# SERDES0 register map
Vendor: Texas Instruments
Registers are 32-bit, read-write, reset 0x0 unless marked. A register's access mark holds for its fields unless they carry their own. Offsets are as the file gives them; [hi:lo] are bit positions; {n}, {i} and the like mark numbered series.

## SERDES0 (part 2 of 2)
0x00 CMU_R000 reset 0x17000000 — The cmu_000 register
  [30:24] CMU_PLL_CTRL1_6_0_O — CMU PLL control 1 register [6:0]
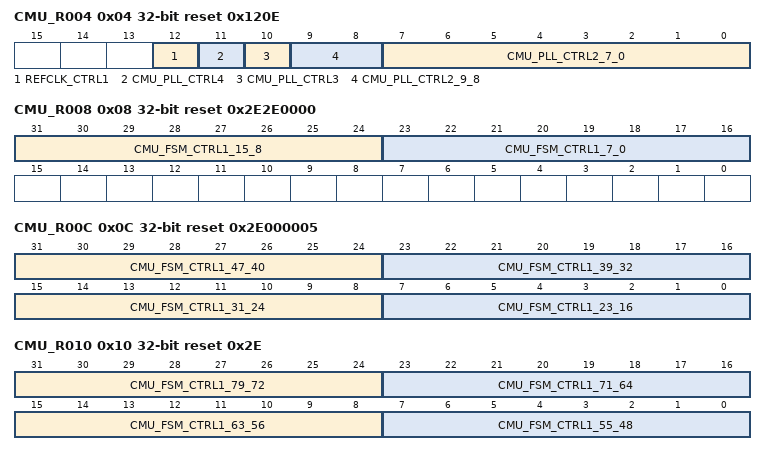
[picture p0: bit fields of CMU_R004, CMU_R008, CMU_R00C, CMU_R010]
0x04 CMU_R004 reset 0x120E — The cmu_004 register
  [12] REFCLK_CTRL1 — Refclk control 1 register
  [11] CMU_PLL_CTRL4 — CMU PLL control 4 register
  [10] CMU_PLL_CTRL3 — CMU PLL control 3 register
  [9:8] CMU_PLL_CTRL2_9_8 — CMU PLL control 2 register [9:8]
  [7:0] CMU_PLL_CTRL2_7_0 — CMU PLL control 2 register [7:0]
0x08 CMU_R008 reset 0x2E2E0000 — The cmu_008 register
  [31:24] CMU_FSM_CTRL1_15_8 — CMU FSM control 1 register 15-8
  [23:16] CMU_FSM_CTRL1_7_0 — CMU FSM control 1 register 7-0
0x0C CMU_R00C reset 0x2E000005 — The cmu_00c register
  [31:24] CMU_FSM_CTRL1_47_40 — CMU FSM control 1 register 47-40
  [23:16] CMU_FSM_CTRL1_39_32 — CMU FSM control 1 register 39-32
  [15:8] CMU_FSM_CTRL1_31_24 — CMU FSM control 1 register 31-24
  [7:0] CMU_FSM_CTRL1_23_16 — CMU FSM control 1 register 23-16
0x10 CMU_R010 reset 0x2E — The cmu_010 register
  [31:24] CMU_FSM_CTRL1_79_72 — CMU FSM control 1 register 79-72
  [23:16] CMU_FSM_CTRL1_71_64 — CMU FSM control 1 register 71-64
  [15:8] CMU_FSM_CTRL1_63_56 — CMU FSM control 1 register 63-56
  [7:0] CMU_FSM_CTRL1_55_48 — CMU FSM control 1 register 55-48
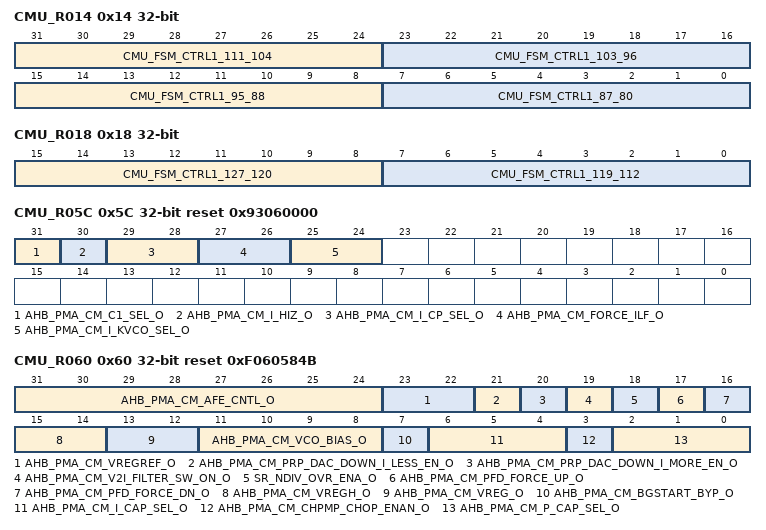
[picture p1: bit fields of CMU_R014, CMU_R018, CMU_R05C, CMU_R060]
0x14 CMU_R014 — The cmu_014 register
  [31:24] CMU_FSM_CTRL1_111_104 — CMU FSM control 1 register 111-104
  [23:16] CMU_FSM_CTRL1_103_96 — CMU FSM control 1 register 103-96
  [15:8] CMU_FSM_CTRL1_95_88 — CMU FSM control 1 register 95-88
  [7:0] CMU_FSM_CTRL1_87_80 — CMU FSM control 1 register 87-80
0x18 CMU_R018 — The cmu_018 register
  [15:8] CMU_FSM_CTRL1_127_120 — CMU FSM control 1 register 127-120
  [7:0] CMU_FSM_CTRL1_119_112 — CMU FSM control 1 register 119-112
0x5C CMU_R05C reset 0x93060000 — The cmu_05c register
  [31] AHB_PMA_CM_C1_SEL_O — CMU LF C1 cap select. Enabling increases C1 cap.
  [30] AHB_PMA_CM_I_HIZ_O — CMU PLL HIZ setting
  [29:28] AHB_PMA_CM_I_CP_SEL_O — Charge pump current gain select.
  [27:26] AHB_PMA_CM_FORCE_ILF_O — CMU loop filter force to common mode
  [25:24] AHB_PMA_CM_I_KVCO_SEL_O — CMU VCO integral path gain
0x60 CMU_R060 reset 0xF060584B — The cmu_060 register
  [31:24] AHB_PMA_CM_AFE_CNTL_O — CMU AFE spares
  [23:22] AHB_PMA_CM_VREGREF_O — CMU reference clock regulator setting
  [21] AHB_PMA_CM_PRP_DAC_DOWN_I_LESS_EN_O — CMU VCO PMOS proportional current decrease
  [20] AHB_PMA_CM_PRP_DAC_DOWN_I_MORE_EN_O — CMU VCO PMOS proportional current increase
  [19] AHB_PMA_CM_V2I_FILTER_SW_ON_O — CMU V2I filter enable
  [18] SR_NDIV_OVR_ENA_O — Override enable for overriding N-div value
  [17] AHB_PMA_CM_PFD_FORCE_UP_O — Force PFD to output up
  [16] AHB_PMA_CM_PFD_FORCE_DN_O — Force PFD to output down
  [15:14] AHB_PMA_CM_VREGH_O — CMU VREGH setting
  [13:12] AHB_PMA_CM_VREG_O — CMU VREG setting
  [11:8] AHB_PMA_CM_VCO_BIAS_O — CMU VCO bias current setting.
  [7] AHB_PMA_CM_BGSTART_BYP_O — Bandgap startup circuit bypass
  [6:4] AHB_PMA_CM_I_CAP_SEL_O — CMU VCO integral path cap select
  [3] AHB_PMA_CM_CHPMP_CHOP_ENAN_O — Charge pump chop enable
  [2:0] AHB_PMA_CM_P_CAP_SEL_O — CMU VCO proportional path cap select
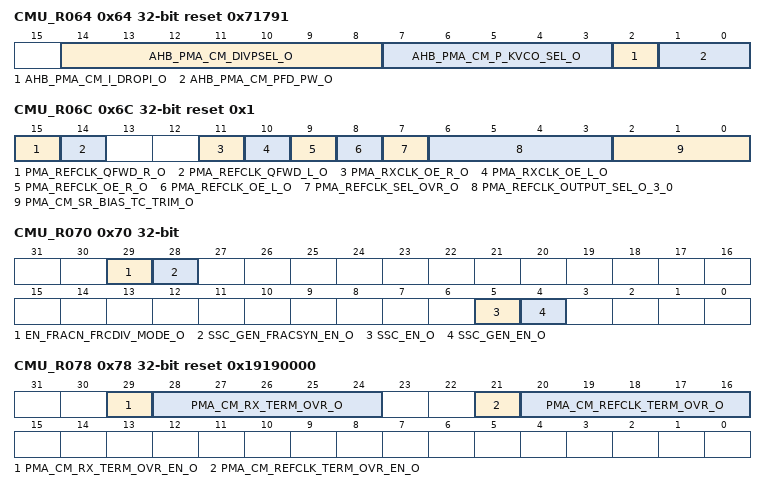
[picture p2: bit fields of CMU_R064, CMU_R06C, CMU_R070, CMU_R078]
0x64 CMU_R064 reset 0x71791 — The cmu_064 register
  [14:8] AHB_PMA_CM_DIVPSEL_O — CMU P-divider setting
  [7:3] AHB_PMA_CM_P_KVCO_SEL_O — CMU PLL KVCO setting
  [2] AHB_PMA_CM_I_DROPI_O — Enable to reduce charge pump reference current
  [1:0] AHB_PMA_CM_PFD_PW_O — PFD pulse width setting
0x6C CMU_R06C reset 0x1 — The cmu_06c register
  [15] PMA_REFCLK_QFWD_R_O — Override for primary IO: refclk_qfwd_r_i Enabled by pma_refclk_sel_ovr_o
  [14] PMA_REFCLK_QFWD_L_O — Override for primary IO: refclk_qfwd_l_i Enabled by pma_refclk_sel_ovr_o
  [11] PMA_RXCLK_OE_R_O — Override for primary IO: rxclk_oe_l_i Enabled by pma_refclk_sel_ovr_o
  [10] PMA_RXCLK_OE_L_O — 'Override for primary IO: rxclk_oe_l_i Enabled by pma_refclk_sel_ovr_o'
  [9] PMA_REFCLK_OE_R_O — 'Override for primary IO: refclk_oe_r_i Enabled by pma_refclk_sel_ovr_o'
  [8] PMA_REFCLK_OE_L_O — Override for primary IO: refclk_oe_l_i Enabled by pma_refclk_sel_ovr_o
  [7] PMA_REFCLK_SEL_OVR_O — Reference clock select override
  [6:3] PMA_REFCLK_OUTPUT_SEL_O_3_0 — Reference clock output select
  [2:0] PMA_CM_SR_BIAS_TC_TRIM_O — sr bias tc trim drving to PMA
0x70 CMU_R070 — The cmu_070 register
  [29] EN_FRACN_FRCDIV_MODE_O — Enable fractional division mode and SSC mode
  [28] SSC_GEN_FRACSYN_EN_O — Enable for SSC generator with Fractional Synthesis
  [5] SSC_EN_O — Active high Enable for SSC block synth or SSC mode
  [4] SSC_GEN_EN_O — Active high Enable for SSC generator SSC mode
0x74 CMU_R074 — The cmu_074 register
0x78 CMU_R078 reset 0x19190000 — The cmu_078 register
  [29] PMA_CM_RX_TERM_OVR_EN_O — Rx Termination override enable
  [28:24] PMA_CM_RX_TERM_OVR_O — Rx Termination override value, every rx lane gets the same value
  [21] PMA_CM_REFCLK_TERM_OVR_EN_O — Refclk Termination override enable
  [20:16] PMA_CM_REFCLK_TERM_OVR_O — Refclk Termination override value
0x7C CMU_R07C reset 0x100920A — The cmu_07c register
  [24] CMU_MASTER_CDN_O — Master reset for CMU
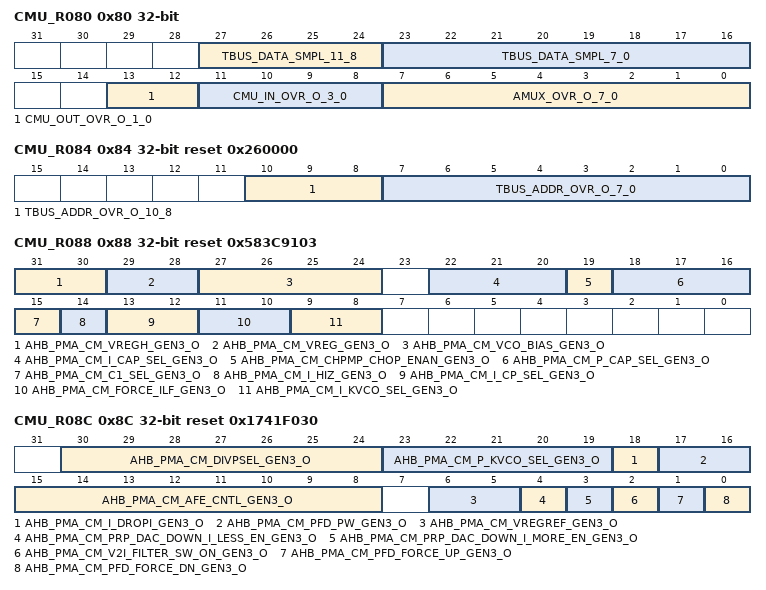
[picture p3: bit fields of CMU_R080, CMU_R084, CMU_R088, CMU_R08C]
0x80 CMU_R080 access per field — The cmu_080 register
  [27:24] TBUS_DATA_SMPL_11_8 ro — Snapshot of digital test bus data [11:8]
  [23:16] TBUS_DATA_SMPL_7_0 ro — Snapshot of digital test bus data [7:0]
  [13:12] CMU_OUT_OVR_O_1_0 rw — Override for Reset_smu_fl
  [11:8] CMU_IN_OVR_O_3_0 rw — Override for following CMU Control Signals [2] - active high, override enable [1] - CMU Powerdown Pin IO [0] - CMU Reset Pin IO
  [7:0] AMUX_OVR_O_7_0 rw — Not used
0x84 CMU_R084 reset 0x260000 — The cmu_084 register
  [10:8] TBUS_ADDR_OVR_O_10_8 — CMU Test Bus address 10-8
  [7:0] TBUS_ADDR_OVR_O_7_0 — CMU Test Bus address 7-0
0x88 CMU_R088 reset 0x583C9103 — The cmu_088 register
  [31:30] AHB_PMA_CM_VREGH_GEN3_O — CMU VREGH setting in gen3 rate Used only in PCIe3 1CMU config
  [29:28] AHB_PMA_CM_VREG_GEN3_O — CMU VREG setting in gen3 rate Used only in PCIe3 1CMU config
  [27:24] AHB_PMA_CM_VCO_BIAS_GEN3_O — CMU VCO bias current setting
  [22:20] AHB_PMA_CM_I_CAP_SEL_GEN3_O — CMU VCO integral path cap select
  [19] AHB_PMA_CM_CHPMP_CHOP_ENAN_GEN3_O — Charge pump chop enable in gen3 rate Used only in PCIe3 1CMU config
  [18:16] AHB_PMA_CM_P_CAP_SEL_GEN3_O — CMU VCO proportional path cap select
  [15] AHB_PMA_CM_C1_SEL_GEN3_O — CMU LF C1 cap select. Enabling increases C1 cap.
  [14] AHB_PMA_CM_I_HIZ_GEN3_O — CMU PLL HIZ setting in gen3 rate Used only in PCIe3 1CMU config
  [13:12] AHB_PMA_CM_I_CP_SEL_GEN3_O — Charge pump current gain select.
  [11:10] AHB_PMA_CM_FORCE_ILF_GEN3_O — CMU LF Force value in gen3 rate Used only in PCIe3 1CMU config
  [9:8] AHB_PMA_CM_I_KVCO_SEL_GEN3_O — CMU VCO proportional current gain
0x8C CMU_R08C reset 0x1741F030 — The cmu_08c register
  [30:24] AHB_PMA_CM_DIVPSEL_GEN3_O — CMU P-divider setting in gen3 rate Used only in PCIe3 1CMU config
  [23:19] AHB_PMA_CM_P_KVCO_SEL_GEN3_O — CMU PLL KVCO setting in gen3 rate Used only in PCIe3 1CMU config
  [18] AHB_PMA_CM_I_DROPI_GEN3_O — Enable to reduce charge pump reference current
  [17:16] AHB_PMA_CM_PFD_PW_GEN3_O — PFD pulse width setting in gen3 rate Used only in PCIe3 1CMU config
  [15:8] AHB_PMA_CM_AFE_CNTL_GEN3_O — CMU AFE spares in gen3 rate Used only in PCIe3 1CMU config
  [6:5] AHB_PMA_CM_VREGREF_GEN3_O — CMU VDREGREF setting
  [4] AHB_PMA_CM_PRP_DAC_DOWN_I_LESS_EN_GEN3_O — CMU VCO PMOS proportional current decrease
  [3] AHB_PMA_CM_PRP_DAC_DOWN_I_MORE_EN_GEN3_O — CMU VCO PMOS proportional current increase
  [2] AHB_PMA_CM_V2I_FILTER_SW_ON_GEN3_O — CMU V2I filter enable in gen3 rate Used only in PCIe3 1CMU config
  [1] AHB_PMA_CM_PFD_FORCE_UP_GEN3_O — Force PFD to output up in gen3 rate Used only in PCIe3 1CMU config
  [0] AHB_PMA_CM_PFD_FORCE_DN_GEN3_O — Force PFD to output down in gen3 rate Used only in PCIe3 1CMU config
0x90 CMU_R090 reset 0x267292 — The cmu_090 register
  [2:0] AHB_PMA_CM_VCOFR_GEN3_O — Override enable for overriding VCOFR value in gen3 rate Used only in PCIe3 1CMU config
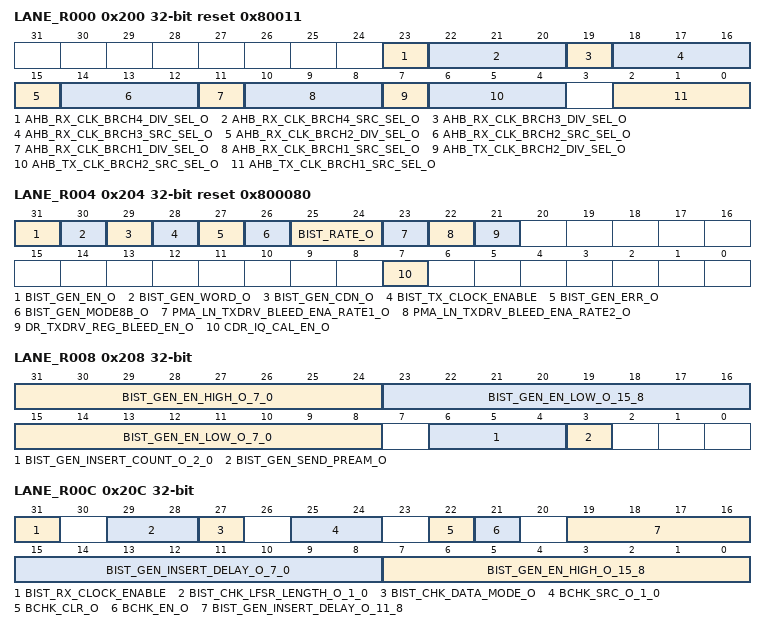
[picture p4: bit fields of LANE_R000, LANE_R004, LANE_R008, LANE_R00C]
0x200 LANE_R000 reset 0x80011 — The lane_000 register
  [23] AHB_RX_CLK_BRCH4_DIV_SEL_O — Clock divider for RX path branch 4: 0-No division, 1- Divide by 2
  [22:20] AHB_RX_CLK_BRCH4_SRC_SEL_O — Clock source select for RX path branch 4 clock : 3'b 000 - qd_ck_i 3'b 001- pma_lX_rxb_iRecovered byte clock 3'b 010 - lnX_clk_i 3'b 011 - pma_lX_txb_iTransmit byte clock 3'b 100 - ck_soc1_int_root 3'b101,3'b 110 - NOT USED 3'b 111 - test_clk_1_i
  [19] AHB_RX_CLK_BRCH3_DIV_SEL_O — Clock divider for RX path branch 3 : 0-No division, 1- Divide by 2
  [18:16] AHB_RX_CLK_BRCH3_SRC_SEL_O — Clock source select for RX path branch 3 clock : 3'b 000 - qd_ck_i 3'b 001- pma_lX_rxb_iRecovered byte clock 3'b 010 - lnX_clk_i 3'b 011 - pma_lX_txb_iTransmit byte clock 3'b 100 - ck_soc1_int_root 3'b101,3'b 110 - NOT USED 3'b 111 - test_clk_1_i
  [15] AHB_RX_CLK_BRCH2_DIV_SEL_O — Clock divider for RX path branch 2 : 0-No division, 1- Divide by 2
  [14:12] AHB_RX_CLK_BRCH2_SRC_SEL_O — Clock source select for RX path branch 2 clock : 3'b 000 - pma_lX_rxb_iRecovered byte clock 3'b 001- pma_lX_txb_iTransmit byte clock 3'b010,3'b011,3'b100,3'b101,3'b 110 - NOT USED 3'b 111 - test_clk_1_i
  [11] AHB_RX_CLK_BRCH1_DIV_SEL_O — Clock divider for RX path branch 1 : 0-No division, 1- Divide by 2
  [10:8] AHB_RX_CLK_BRCH1_SRC_SEL_O — Clock source select for RX path branch 1 clock : 3'b 000 - pma_lX_rxb_iRecovered byte clock 3'b 001- pma_lX_txb_iTransmit byte clock 3'b010,3'b011,3'b100,3'b101,3'b 110 - NOT USED 3'b 111 - test_clk_1_i
  [7] AHB_TX_CLK_BRCH2_DIV_SEL_O — Clock divider for TX path branch 2 : 0-No division, 1- Divide by 2
  [6:4] AHB_TX_CLK_BRCH2_SRC_SEL_O — Clock source select for TX path branch 2 clock : 3'b 000 - lnX_clk_i 3'b 001- qd_ck_i 3'b 011 - ck_soc1_int_root 3'b010,3'b100,3'b101,3'b 110 - NOT USED 3'b 111 - test_clk_0_i
  [2:0] AHB_TX_CLK_BRCH1_SRC_SEL_O — Clock source select for TX path branch 1 clock : 3'b 000 - lnX_clk_i 3'b 001- qd_ck_i 3'b 010 - pma_lX_rxb_iRecovered byte clock 3'b 011 - ck_soc1_int_root 3'b100,3'b101,3'b 110 - NOT USED 3'b 111 - test_clk_0_i
0x204 LANE_R004 reset 0x800080 — The lane_004 register
  [31] BIST_GEN_EN_O — Bist generator enable. 0 - Bist generator idle. 1 - Bist generator generates data
  [30] BIST_GEN_WORD_O — Bist generator word enable. 0 - Bist generator generates single word 8 or 10 1 - Bist generator generates double word 16 or 20
  [29] BIST_GEN_CDN_O — Bist generator master reset.
  [28] BIST_TX_CLOCK_ENABLE — Active HIGH clock enable signal for the BIST transmit clock
  [27] BIST_GEN_ERR_O — Bist generator error insert enable. 0 - BIST generator outputs normal pattern. 1 - BIST generator outputs erroneous pattern.
  [26] BIST_GEN_MODE8B_O — Bist generator 8b mode control 0 - Generated data word is 10 bits 1 - Generated data word is 8 bits
  [25:24] BIST_RATE_O — Rate control for BIST
  [23] PMA_LN_TXDRV_BLEED_ENA_RATE1_O — txdrv regulator bleed enable for gen3 rate
  [22] PMA_LN_TXDRV_BLEED_ENA_RATE2_O — txdrv regulator bleed enable for gen2 rate
  [21] DR_TXDRV_REG_BLEED_EN_O — txdrv regulator bleed enable for gen1 rate
  [7] CDR_IQ_CAL_EN_O — IQ Calibration enable
0x208 LANE_R008 — The lane_008 register
  [31:24] BIST_GEN_EN_HIGH_O_7_0 — Bist generator high-period control. Refer to bist_gen_en_low_o and BIST documentation for further information.
  [23:16] BIST_GEN_EN_LOW_O_15_8 — Bist generator low-period control. If not 0, output data enable will be low for this number of words, and then high for en_high_i_X:0 number of words, repeating. If 0, data output enable will be asserted for entire test.
  [15:8] BIST_GEN_EN_LOW_O_7_0 — Bist generator low-period control. If not 0, output data enable will be low for this number of words, and then high for en_high_i_X:0 number of words, repeating. If 0, data output enable will be asserted for entire test.
  [6:4] BIST_GEN_INSERT_COUNT_O_2_0 — Bist generator - Number of bist_chk_insert_word_i words to insert at a time. If 0, no word is ever inserted into the stream. In 20-bit mode, the product of bist_gen_insert_length x bist_gen_insert_count must be even.
  [3] BIST_GEN_SEND_PREAM_O — Bist generator preamble send. Valid only if generator enabled. 0 - Bist generator sends normal data. 1 - Bist generator sends preamble.
0x20C LANE_R00C — The lane_00c register
  [31] BIST_RX_CLOCK_ENABLE — Active HIGH clock enable signal for the BIST receive clock
  [29:28] BIST_CHK_LFSR_LENGTH_O_1_0 — BIST PRBS pattern selector.
  [27] BIST_CHK_DATA_MODE_O — Bist checker mode select. 0X0 UDP pattern. 0x1 PRBS pattern
  [25:24] BCHK_SRC_O_1_0 — BIST checker source. 0 - BIST uses output of initial RX polbit before Symbol Aligner 1 - BIST uses output of Symbol Aligner before Elastic Buffer 2 - BIST uses output of RX loopback mux before Decoder and Polbits 3 - BIST uses output of reg1 flop bank before Interface blocks
  [22] BCHK_CLR_O — BIST checker clear signal. Zeroes error counter output. Does NOT go through the RX BIST control block
  [21] BCHK_EN_O — BIST checker enable Enables BIST RX Control block, which enables the actual BIST RX block when appropriate
  [19:16] BIST_GEN_INSERT_DELAY_O_11_8 — Bist generator - Number of words between insert word insertions. Insertions are done in both pream and data transmission. In 20-bit mode, this number must be even.
  [15:8] BIST_GEN_INSERT_DELAY_O_7_0 — Bist generator - Number of words between insert word insertions. Insertions are done in both pream and data transmission. In 20-bit mode, this number must be even.
  [7:0] BIST_GEN_EN_HIGH_O_15_8 — Bist generator high-period control. Refer to bist_gen_en_low_o and BIST documentation for further information.
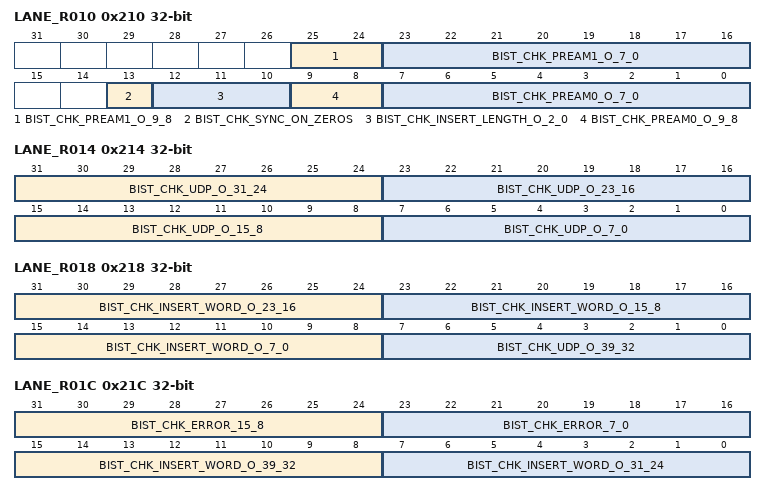
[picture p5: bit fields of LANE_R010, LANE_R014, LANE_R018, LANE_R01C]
0x210 LANE_R010 — The lane_010 register
  [25:24] BIST_CHK_PREAM1_O_9_8 — BIST Check Preamble
  [23:16] BIST_CHK_PREAM1_O_7_0 — BIST Check Preamble
  [13] BIST_CHK_SYNC_ON_ZEROS — Setting this bit allows BIST to sync to RX value of zero
  [12:10] BIST_CHK_INSERT_LENGTH_O_2_0 — BIST Checker Insert word length.
  [9:8] BIST_CHK_PREAM0_O_9_8 — Bist checker preamble word 0. When in 8b mode, and prior to the 8b/10b encoder, bit 8 is expected to be the K indicator. This word should correspond to the alignment character used for the symbol alignment block.
  [7:0] BIST_CHK_PREAM0_O_7_0 — Bist checker preamble word 0. When in 8b mode, and prior to the 8b/10b encoder, bit 8 is expected to be the K indicator. This word should correspond to the alignment character used for the symbol alignment block.
0x214 LANE_R014 — The lane_014 register
  [31:24] BIST_CHK_UDP_O_31_24 — BIST Check User-defined pattern
  [23:16] BIST_CHK_UDP_O_23_16 — BIST Check User-defined pattern
  [15:8] BIST_CHK_UDP_O_15_8 — BIST Check User-defined pattern
  [7:0] BIST_CHK_UDP_O_7_0 — BIST checker 40-bit user defined data pattern. In 10-bit mode, corresponds to 4 10-bit words. In 8-bit mode, corresponds to 5 8-bit words. K code is assumed to be 0 in 8-bit mode.
0x218 LANE_R018 — The lane_018 register
  [31:24] BIST_CHK_INSERT_WORD_O_23_16 — Bist checker insertion word.
  [23:16] BIST_CHK_INSERT_WORD_O_15_8 — Bist checker insertion word.
  [15:8] BIST_CHK_INSERT_WORD_O_7_0 — Bist checker insertion word.
  [7:0] BIST_CHK_UDP_O_39_32 — BIST Check User-defined pattern
0x21C LANE_R01C access per field — The lane_01c register
  [31:24] BIST_CHK_ERROR_15_8 ro — Bist errors detected
  [23:16] BIST_CHK_ERROR_7_0 ro — Bist errors detected
  [15:8] BIST_CHK_INSERT_WORD_O_39_32 rw — Bist checker insertion word.
  [7:0] BIST_CHK_INSERT_WORD_O_31_24 rw — Bist checker insertion word.
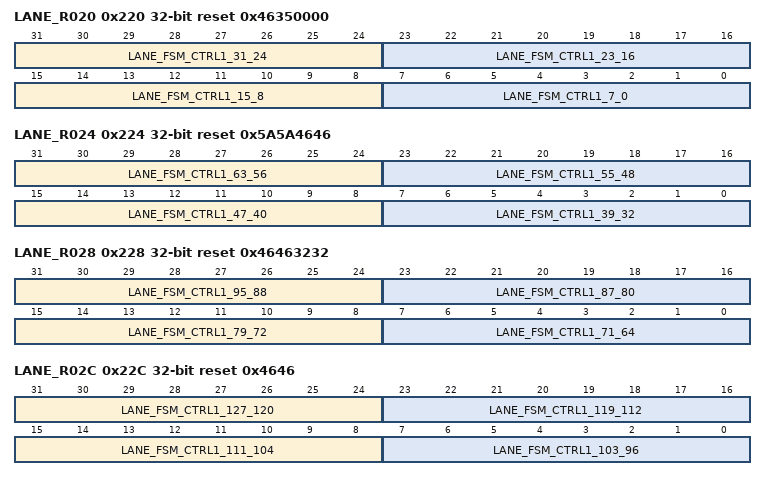
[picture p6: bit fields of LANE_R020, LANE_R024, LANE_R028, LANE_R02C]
0x220 LANE_R020 reset 0x46350000 — The lane_020 register
  [31:24] LANE_FSM_CTRL1_31_24 — LANE FSM control 1 register 31-24
  [23:16] LANE_FSM_CTRL1_23_16 — LANE FSM control 1 register 23-16
  [15:8] LANE_FSM_CTRL1_15_8 — LANE FSM control 1 register 15-8
  [7:0] LANE_FSM_CTRL1_7_0 — LANE FSM control 1 register 7-0
0x224 LANE_R024 reset 0x5A5A4646 — The lane_024 register
  [31:24] LANE_FSM_CTRL1_63_56 — LANE FSM control 1 register 63-56
  [23:16] LANE_FSM_CTRL1_55_48 — LANE FSM control 1 register 55-48
  [15:8] LANE_FSM_CTRL1_47_40 — LANE FSM control 1 register 47-40
  [7:0] LANE_FSM_CTRL1_39_32 — LANE FSM control 1 register 39-32
0x228 LANE_R028 reset 0x46463232 — The lane_028 register
  [31:24] LANE_FSM_CTRL1_95_88 — LANE FSM control 1 register 95-88
  [23:16] LANE_FSM_CTRL1_87_80 — LANE FSM control 1 register 87-80
  [15:8] LANE_FSM_CTRL1_79_72 — LANE FSM control 1 register 79-72
  [7:0] LANE_FSM_CTRL1_71_64 — LANE FSM control 1 register 71-64
0x22C LANE_R02C reset 0x4646 — The lane_02c register
  [31:24] LANE_FSM_CTRL1_127_120 — LANE FSM control 1 register 127-120
  [23:16] LANE_FSM_CTRL1_119_112 — LANE FSM control 1 register 119-112
  [15:8] LANE_FSM_CTRL1_111_104 — LANE FSM control 1 register 111-104
  [7:0] LANE_FSM_CTRL1_103_96 — LANE FSM control 1 register 103-96
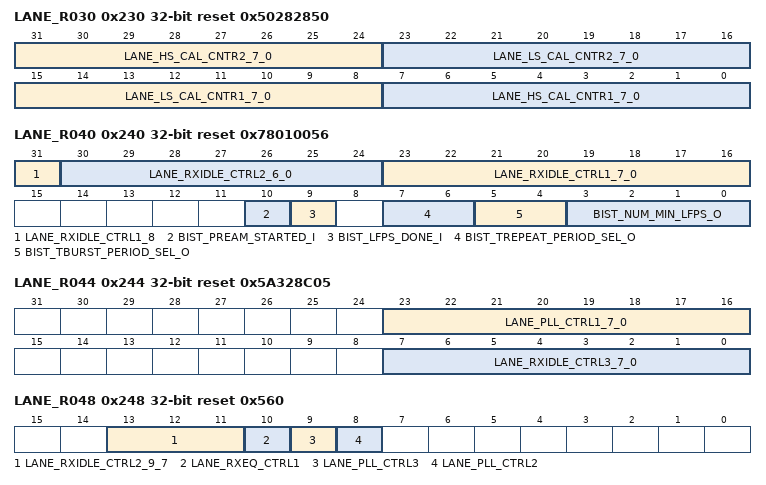
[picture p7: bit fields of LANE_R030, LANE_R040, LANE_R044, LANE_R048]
0x230 LANE_R030 reset 0x50282850 — The lane_030 register
  [31:24] LANE_HS_CAL_CNTR2_7_0 — LANE High speed calibration counter 2 length [7:0]
  [23:16] LANE_LS_CAL_CNTR2_7_0 — LANE Low speed calibration counter 2 length [7:0]
  [15:8] LANE_LS_CAL_CNTR1_7_0 — LANE Low speed calibration counter 1 length [7:0]
  [7:0] LANE_HS_CAL_CNTR1_7_0 — LANE High speed calibration counter 1 length [7:0]
0x240 LANE_R040 access per field reset 0x78010056 — The lane_040 register
  [31] LANE_RXIDLE_CTRL1_8 rw — LANE RXIDLE control 1 register [8]
  [30:24] LANE_RXIDLE_CTRL2_6_0 rw — LANE RXIDLE control 2 register [6:0]
  [23:16] LANE_RXIDLE_CTRL1_7_0 rw — LANE RXIDLE control 1 register [7:0]
  [10] BIST_PREAM_STARTED_I ro — Preamble transmission started during BIST
  [9] BIST_LFPS_DONE_I ro — Minimum LFPS sending completed during BIST
  [7:6] BIST_TREPEAT_PERIOD_SEL_O rw — Trepeat period select during BIST 00 = 6 us 01 = 8 us - 10 = 10 us - 11 = 14 us
  [5:4] BIST_TBURST_PERIOD_SEL_O rw — Tburst period select during BIST 00 = 0.6 us 01 = 0.8 us 10 = 1.0 us 11 = 1.4 us
  [3:0] BIST_NUM_MIN_LFPS_O rw — Minimum number of LFPS bursts to be send during BIST
0x244 LANE_R044 reset 0x5A328C05 — The lane_044 register
  [23:16] LANE_PLL_CTRL1_7_0 — LANE PLL control 1 register [7:0]
  [7:0] LANE_RXIDLE_CTRL3_7_0 — LANE RXIDLE control 3 register [7:0]
0x248 LANE_R048 reset 0x560 — The lane_048 register
  [13:11] LANE_RXIDLE_CTRL2_9_7 — LANE RXIDLE control 2 register [9:7]
  [10] LANE_RXEQ_CTRL1 — LANE RXEQ control 1 register
  [9] LANE_PLL_CTRL3 — LANE PLL control 3 register
  [8] LANE_PLL_CTRL2 — LANE PLL control 2 register
0x24C LANE_R04C reset 0xC10000 — The lane_04c register
  [24] SYM_ALIGN_BYPASS_O — Asserting this register will bypass the symbol aligner
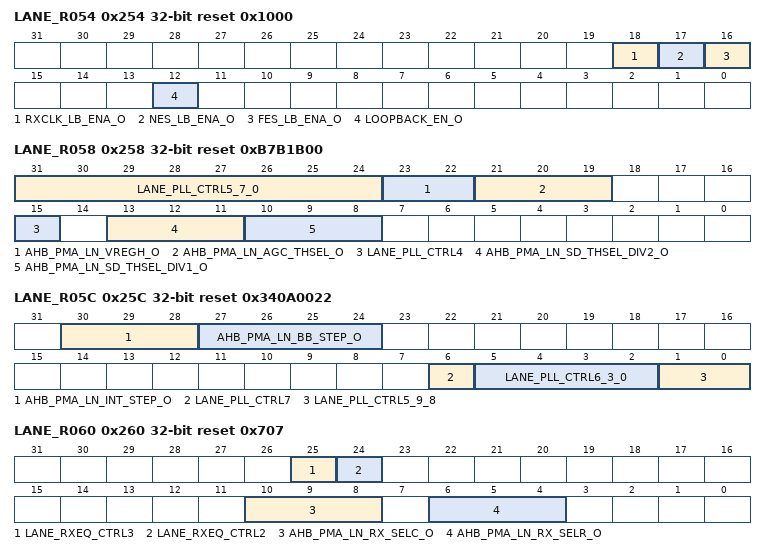
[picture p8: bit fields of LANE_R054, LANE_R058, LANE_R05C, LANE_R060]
0x254 LANE_R054 reset 0x1000 — The lane_054 register
  [18] RXCLK_LB_ENA_O — HS recovered clock to transmit loopback enable.
  [17] NES_LB_ENA_O — NES loopback enable.
  [16] FES_LB_ENA_O — FES loopback enable.
  [12] LOOPBACK_EN_O — Control signal to force decoder into loopback mode
0x258 LANE_R058 reset 0xB7B1B00 — The lane_058 register
  [31:24] LANE_PLL_CTRL5_7_0 — LANE PLL control 5 register [7:0]
  [23:22] AHB_PMA_LN_VREGH_O — Regulator VREGH setting
  [21:19] AHB_PMA_LN_AGC_THSEL_O — AGC threshold select
  [15] LANE_PLL_CTRL4 — RX FL calibration clock DIV4 enable
  [13:11] AHB_PMA_LN_SD_THSEL_DIV2_O — Signal detect threshold select for div-by-2 rate
  [10:8] AHB_PMA_LN_SD_THSEL_DIV1_O — Signal detect threshold select for Full rate
0x25C LANE_R05C reset 0x340A0022 — The lane_05c register
  [30:28] AHB_PMA_LN_INT_STEP_O — CDR int step
  [27:24] AHB_PMA_LN_BB_STEP_O — CDR bb_step
  [6] LANE_PLL_CTRL7 — LANE PLL control 7 register
  [5:2] LANE_PLL_CTRL6_3_0 — LANE PLL control 6 register [3:0]
  [1:0] LANE_PLL_CTRL5_9_8 — LANE PLL control 5 register [9:8]
0x260 LANE_R060 reset 0x707 — The lane_060 register
  [25] LANE_RXEQ_CTRL3 — LANE RXEQ control 3 register
  [24] LANE_RXEQ_CTRL2 — LANE RXEQ control 2 register
  [10:8] AHB_PMA_LN_RX_SELC_O — CTLE C degeneration select
  [6:4] AHB_PMA_LN_RX_SELR_O — CTLE R degeneration select
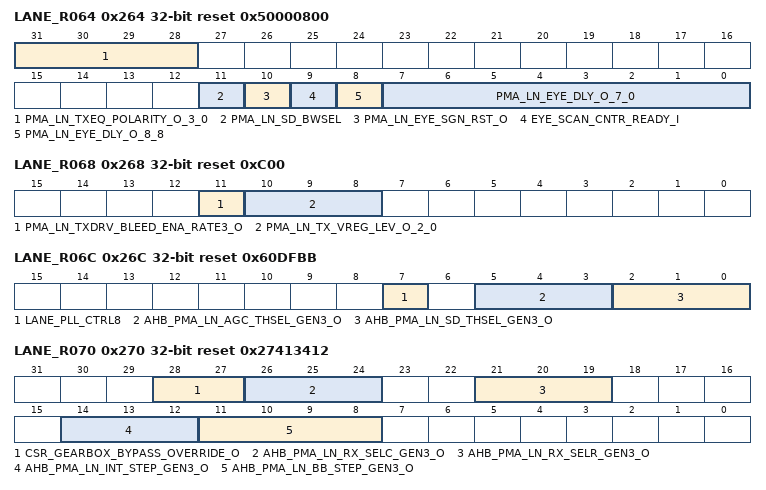
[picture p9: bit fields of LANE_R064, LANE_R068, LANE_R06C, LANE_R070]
0x264 LANE_R064 access per field reset 0x50000800 — The lane_064 register
  [31:28] PMA_LN_TXEQ_POLARITY_O_3_0 rw — TX coefficient polarity enable. Set to '1' for negative polarity. bit 0: Cm bit 1: C0 bit 2: C1
  [11] PMA_LN_SD_BWSEL rw — RX signal detector bandwidth select. 0: Nominal bandwidth 1: 10% higher bandwidth
  [10] PMA_LN_EYE_SGN_RST_O rw — Reset signal for eye alignment mechanism.
  [9] EYE_SCAN_CNTR_READY_I ro — Counter ready signal from eye scan counter block
  [8] PMA_LN_EYE_DLY_O_8_8 rw — On-chip eye diagram X-direction offset control: Bits 0-1: Coarse x-direction offset, in steps of 1/2UI - note bit reversal Bits 2-8: Fine x-direction offset, note bit reversal
  [7:0] PMA_LN_EYE_DLY_O_7_0 rw — On-chip eye diagram X-direction offset control: Bit 0: unused Bits 1-2: Coarse x-direction offset, in steps of 1/2UI - note bit reversal Bits 3-9: Fine x-direction offset, note bit reversal
0x268 LANE_R068 reset 0xC00 — The lane_068 register
  [11] PMA_LN_TXDRV_BLEED_ENA_RATE3_O — TX bleed enable
  [10:8] PMA_LN_TX_VREG_LEV_O_2_0 — TX driver regulator voltage setting.
0x26C LANE_R06C reset 0x60DFBB — The lane_06c register
  [7] LANE_PLL_CTRL8 — LANE PLL control 8 register
  [5:3] AHB_PMA_LN_AGC_THSEL_GEN3_O — AGC threshold select for Gen3
  [2:0] AHB_PMA_LN_SD_THSEL_GEN3_O — Signal detect threshold select for Gen3
0x270 LANE_R070 reset 0x27413412 — The lane_070 register
  [28:27] CSR_GEARBOX_BYPASS_OVERRIDE_O — Bypass override for gearbox.
  [26:24] AHB_PMA_LN_RX_SELC_GEN3_O — CTLE R degeneration select for Gen3
  [21:19] AHB_PMA_LN_RX_SELR_GEN3_O — CTLE R degeneration select for Gen3
  [14:12] AHB_PMA_LN_INT_STEP_GEN3_O — CDR int step for Gen3
  [11:8] AHB_PMA_LN_BB_STEP_GEN3_O — CDR bb_step for Gen3
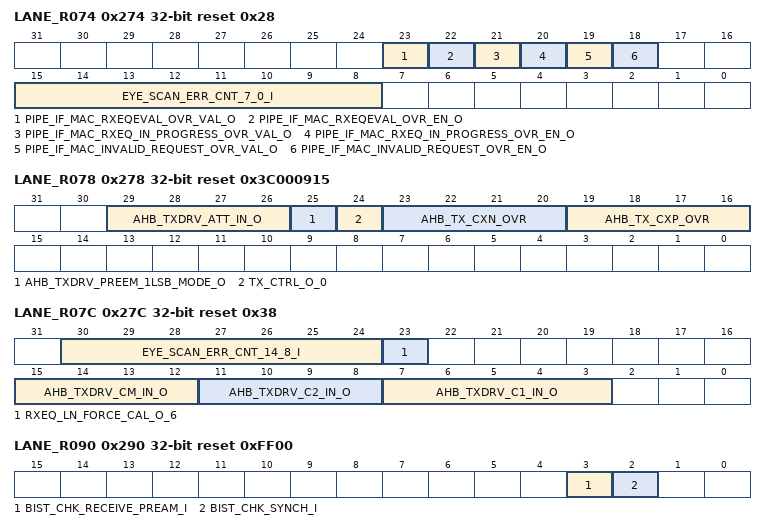
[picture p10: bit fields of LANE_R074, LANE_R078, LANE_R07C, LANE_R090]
0x274 LANE_R074 access per field reset 0x28 — The lane_074 register
  [23] PIPE_IF_MAC_RXEQEVAL_OVR_VAL_O rw — Override value for MAC input rxeqeval
  [22] PIPE_IF_MAC_RXEQEVAL_OVR_EN_O rw — Override enable for MAC input rxeqeval
  [21] PIPE_IF_MAC_RXEQ_IN_PROGRESS_OVR_VAL_O rw — Override value for MAC input rxeq in progress
  [20] PIPE_IF_MAC_RXEQ_IN_PROGRESS_OVR_EN_O rw — Override enable for MAC input rxeq in progress
  [19] PIPE_IF_MAC_INVALID_REQUEST_OVR_VAL_O rw — Override value for MAC input invalid request
  [18] PIPE_IF_MAC_INVALID_REQUEST_OVR_EN_O rw — Override enable for MAC input invalid request
  [15:8] EYE_SCAN_ERR_CNT_7_0_I ro — Error count from eye scan counter block.
0x278 LANE_R078 reset 0x3C000915 — The lane_078 register
  [29:26] AHB_TXDRV_ATT_IN_O — TX Control override for txdrv_att_in
  [25] AHB_TXDRV_PREEM_1LSB_MODE_O — TX Control override for txdrv_preem_1lsb_mode
  [24] TX_CTRL_O_0 — TX Control override enable. Bit 0: txdrv_sel_sw_map Bit 1: not currently used
  [23:20] AHB_TX_CXN_OVR — override calibrated txterm value
  [19:16] AHB_TX_CXP_OVR — override calibrated txterm value
0x27C LANE_R07C access per field reset 0x38 — The lane_07c register
  [30:24] EYE_SCAN_ERR_CNT_14_8_I ro — Error count from eye scan counter block.
  [23] RXEQ_LN_FORCE_CAL_O_6 rw — This bit has similar function as rxeq_force_cal_en_o in COMLANE CSR. It is logically OR'ed with the bit in COMLANE
  [15:12] AHB_TXDRV_CM_IN_O rw — TX Control override for txdrv_cm_in
  [11:8] AHB_TXDRV_C2_IN_O rw — TX Control override for txdrv_c2_in
  [7:3] AHB_TXDRV_C1_IN_O rw — TX Control override for txdrv_c1_in
0x280 LANE_R080 access per field reset 0xA00000 — The lane_080 register
  [4:0] EYE_SCAN_ERR_CNT_19_15_I ro — Error count from eye scan counter block.
0x288 LANE_R088 — The lane_088 register
  [15:8] LANE_RXIDLE_CTRL4_7_0 — LANE RXIDLE control 4 register [7:0]
0x28C LANE_R08C — The lane_08c register
  [24] LANE_RXEQ_CTRL6 — LANE RXEQ control 6 register
0x290 LANE_R090 access per field reset 0xFF00 — The lane_090 register
  [3] BIST_CHK_RECEIVE_PREAM_I ro — sync receive preamble status form bist rx.
  [2] BIST_CHK_SYNCH_I ro — sync check status form bist rx.
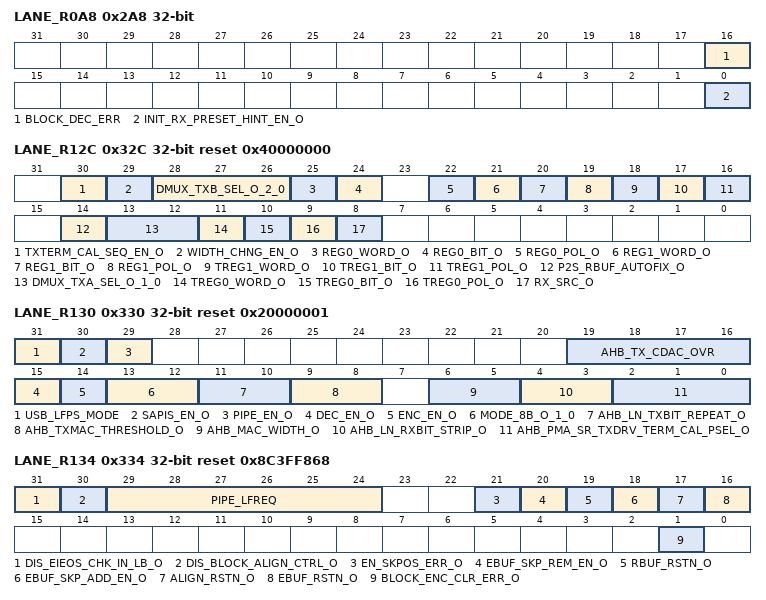
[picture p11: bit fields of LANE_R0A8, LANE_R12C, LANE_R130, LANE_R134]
0x2A8 LANE_R0A8 access per field — The lane_0a8 register
  [16] BLOCK_DEC_ERR ro — decoder sync header error
  [0] INIT_RX_PRESET_HINT_EN_O rw — Enable for primary input lnx_rx_preset_hint during init cal.
0x32C LANE_R12C reset 0x40000000 — The lane_12c register
  [30] TXTERM_CAL_SEQ_EN_O — Txterm calibration enable
  [29] WIDTH_CHNG_EN_O — Enable bit for width_chng module
  [28:26] DMUX_TXB_SEL_O_2_0 — Transmit mux B data input select enable.
  [25] REG0_WORD_O — Reg0 data bank word order select. 0 - Normal word order used - words are not modified. 1 - Flipped word order used - lower and upper words are flipped.
  [24] REG0_BIT_O — Reg0 data bank bit order select. 0 - Normal bit order used. Bit order unmodified. 1 - Reversed bit order used. Bit order in each word reversed.
  [22] REG0_POL_O — Used as Reg0 polarity select
  [21] REG1_WORD_O — Reg1 data bank word order select. 0 - Normal word order used - words are not modified. 1 - Flipped word order used - lower and upper words are flipped.
  [20] REG1_BIT_O — Reg1 data bank bit order select. 0 - Normal bit order used. Bit order unmodified. 1 - Reversed bit order used. Bit order in each word reversed.
  [19] REG1_POL_O — Reg1 data bank polarity select. 0 - Data is unmodified. 1 - Data polarity is reversed.
  [18] TREG1_WORD_O — TReg1 data bank word order select. 0 - Normal word order used - words are not modified. 1 - Flipped word order used - lower and upper words are flipped.
  [17] TREG1_BIT_O — TReg1 data bank bit order select. 0 - Normal bit order used. Bit order unmodified. 1 - Reversed bit order used. Bit order in each word reversed.
  [16] TREG1_POL_O — TReg1 data bank polarity select. 0 - Data is unmodified. 1 - Data polarity is reversed.
  [14] P2S_RBUF_AUTOFIX_O — P2S ring buffer autofix enable. 0 - Ring buffer will not attempt to fix overflow / underflows 1 - Ring buffer will reset upon detection of overflow/underflow
  [13:12] DMUX_TXA_SEL_O_1_0 — Transmit mux A data input select.
  [11] TREG0_WORD_O — TReg0 data bank word order select. 0 - Normal word order used - words are not modified. 1 - Flipped word order used - lower and upper words are flipped.
  [10] TREG0_BIT_O — TReg0 data bank bit order select. 0 - Normal bit order used. Bit order unmodified. 1 - Reversed bit order used. Bit order in each word reversed.
  [9] TREG0_POL_O — TReg0 data bank polarity select. 0 - Data is unmodified. 1 - Data polarity is reversed.
  [8] RX_SRC_O — RX loopback mux input select. 0 - Output of mux is normal RX data path. 1 - Output of mux is output from 8b/10b encoder.
0x330 LANE_R130 reset 0x20000001 — The lane_130 register
  [31] USB_LFPS_MODE — Signal Detect USB mode enable. When disabled it bypasses LFPS detection and makes usb mode 0 to PMA
  [30] SAPIS_EN_O — SAPIS interface block enable.
  [29] PIPE_EN_O — PIPE interface block enable.
  [19:16] AHB_TX_CDAC_OVR — TX termination calibration DAC override. Signal ahb_tx_term_en_cal_ovr must also be asserted to take effect.
  [15] DEC_EN_O — 8b/10b decoder enable.
  [14] ENC_EN_O — 8b/10b encoder enable.
  [13:12] MODE_8B_O_1_0 — 8b mode control, blocks prior AFE side of 8b/10b enc/dec 0 - Data word is 10 bits 1 - Data word 8 bits
  [11:10] AHB_LN_TXBIT_REPEAT_O — Bit stuffing on txdata from PCS to PMA, bit stripping on rxdata from PMA to PCS 00: no bit stuffing nor stripping 01: 2x bit stuffing and stripping 10: NOT USED 11: 4x bit stuffing and stripping
  [9:8] AHB_TXMAC_THRESHOLD_O — An internal FIFO is included to handle the communication between the external 64-bit data and the internal 20-bit data. The reading operation will begin only when the difference between the write pointer and read pointer for this FIFO reaches ahb_txmac_threshold_o.
  [6:5] AHB_MAC_WIDTH_O — Data width selector for PCS/MAC interface. 00: GigE or XAUI 01: GigE or XAUI 10: RXAUI 11: XFI
  [4:3] AHB_LN_RXBIT_STRIP_O — Bit stripping on rxdata from PMA to PCS 00: no bit stripping 01: 2x bit stripping 10: NOT USED 11: 4x bit stripping
  [2:0] AHB_PMA_SR_TXDRV_TERM_CAL_PSEL_O — tx termination calibration comparator threshold select
0x334 LANE_R134 reset 0x8C3FF868 — The lane_134 register
  [31] DIS_EIEOS_CHK_IN_LB_O — Disables the EIEOS check in loopback
  [30] DIS_BLOCK_ALIGN_CTRL_O — Disables the primary input lnX_block_align_control
  [29:24] PIPE_LFREQ — LF value for full swing
  [21] EN_SKPOS_ERR_O — Enables skpos error status propagation in Gen3
  [20] EBUF_SKP_REM_EN_O — Elastic buffer SKP remove enable
  [19] RBUF_RSTN_O — TX FIFO synchronous reset
  [18] EBUF_SKP_ADD_EN_O — Elastic buffer SKP add enable
  [17] ALIGN_RSTN_O — Synchronous clear for block/symbol aligner
  [16] EBUF_RSTN_O — Synchronous clear for elastic buffer
  [1] BLOCK_ENC_CLR_ERR_O — 128b/130b encoder clear error
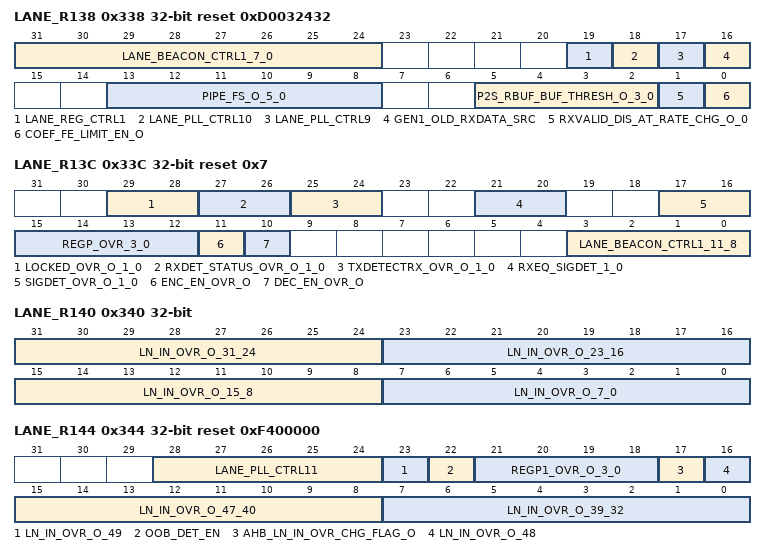
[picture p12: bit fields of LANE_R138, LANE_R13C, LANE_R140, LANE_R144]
0x338 LANE_R138 reset 0xD0032432 — The lane_138 register
  [31:24] LANE_BEACON_CTRL1_7_0 — LANE beacon control 1 register [7:0]
  [19] LANE_REG_CTRL1 — LANE regulator control 1 register
  [18] LANE_PLL_CTRL10 — LANE PLL control 10 register
  [17] LANE_PLL_CTRL9 — LANE PLL control 9 register
  [16] GEN1_OLD_RXDATA_SRC — Mux select for data input to polbit_reg0 0:pma_ln_dfe_err_i , 1: pma_ln_rxdata_i
  [13:8] PIPE_FS_O_5_0 — Full swing value
  [5:2] P2S_RBUF_BUF_THRESH_O_3_0 — TX FIFO: specifies how far write pointer need to be ahead of read pointer before almost_full_o is asserted
  [1] RXVALID_DIS_AT_RATE_CHG_O_0 — Value 1 forces rxvalid to be deasserted during rate change to gen 3
  [0] COEF_FE_LIMIT_EN_O — FE TxEq Co-efficient Limiting Enable control
0x33C LANE_R13C reset 0x7 — The lane_13c register
  [29:28] LOCKED_OVR_O_1_0 — Override signal for symbol align locked output. Bit 1 is the override enable, and bit 0 is the override value.
  [27:26] RXDET_STATUS_OVR_O_1_0 — Override signal for txdetectrx output - bit 1 is override enable, bit 0 is override value.
  [25:24] TXDETECTRX_OVR_O_1_0 — Override signal for txdetectrx input - bit 1 is override enable, bit 0 is override value.
  [21:20] RXEQ_SIGDET_1_0 — Override enable for DFE signal detect indicator input. Bit 1 is overide enable , 0 is overide value
  [17:16] SIGDET_OVR_O_1_0 — Bit[0]: Overide value. Bit[1] :Override enable for signal detect output
  [15:12] REGP_OVR_3_0 — Bit[3]: Polarity register block input override enable. Bit[0]: Overide values for polarty Bit[1]: Overide values for bit reverse Bit[2]: Overide values for word reverse
  [11] ENC_EN_OVR_O — Enables 16b/20b encoder
  [10] DEC_EN_OVR_O — Enables 16b/20b decoder
  [3:0] LANE_BEACON_CTRL1_11_8 — LANE beacon control 1 register [11:8]
0x340 LANE_R140 — The lane_140 register
  [31:24] LN_IN_OVR_O_31_24 — Override for primary lane inputs For PCIE3 mode : 0 : override enable 1 : override for lnx_rstn [3:2] : override for lnx_rate [5:4] : override for lnX_pd [48:6] : override for lnx_ctrl For SAPIS Mode : 0 : override enable 1 : override for lnx_rstn { [17:15], [3:2]} : override for lnx_rate [5:4] : override for lnX_pd [14:6] : override for lnx_ctrl [48:15] : not used [48:15] : not used
  [23:16] LN_IN_OVR_O_23_16 — Override for primary lane inputs For PCIE3 mode : 0 : override enable 1 : override for lnx_rstn [3:2] : override for lnx_rate [5:4] : override for lnX_pd [48:6] : override for lnx_ctrl For SAPIS Mode : 0 : override enable 1 : override for lnx_rstn { [17:15], [3:2]} : override for lnx_rate [5:4] : override for lnX_pd [14:6] : override for lnx_ctrl [48:15] : not used [48:15] : not used
  [15:8] LN_IN_OVR_O_15_8 — Override for primary lane inputs For PCIE3 mode : 0 : override enable 1 : override for lnx_rstn [3:2] : override for lnx_rate [5:4] : override for lnX_pd [48:6] : override for lnx_ctrl For SAPIS Mode : 0 : override enable 1 : override for lnx_rstn { [17:15], [3:2]} : override for lnx_rate [5:4] : override for lnX_pd [14:6] : override for lnx_ctrl [48:15] : not used [48:15] : not used
  [7:0] LN_IN_OVR_O_7_0 — Override for primary lane inputs For PCIE3 mode : 0 : override enable 1 : override for lnx_rstn [3:2] : override for lnx_rate [5:4] : override for lnX_pd [48:6] : override for lnx_ctrl For SAPIS Mode : 0 : override enable 1 : override for lnx_rstn { [17:15], [3:2]} : override for lnx_rate [5:4] : override for lnX_pd [14:6] : override for lnx_ctrl [48:15] : not used [48:15] : not used
0x344 LANE_R144 reset 0xF400000 — The lane_144 register
  [28:24] LANE_PLL_CTRL11 — Delay between cisel assertion and enabling the CDR loop pma_lX_dlpf_ext_ena=0 R-platform requires 150ns delay
  [23] LN_IN_OVR_O_49
  [22] OOB_DET_EN — OOB detect enable
  [21:18] REGP1_OVR_O_3_0 — Overrides for polbit block polbit_regp1 Bit[3]: Polarity register block input override enable. Bit[0]: Overide values for polarty Bit[1]: Overide values for bit reverse Bit[2]: Overide values for word reverse
  [17] AHB_LN_IN_OVR_CHG_FLAG_O — Flag to guard around each write to lnX_in_ovr_o_14_1 when the lane is out of reset. Set this bit to '1' before writing to the corresponding lnX_in_ovr_o_14_1 and set it back to '0' after the write. It is not needed for configuration writes.
  [16] LN_IN_OVR_O_48 — Override for primary lane inputs For PCIE3 mode : 0 : override enable 1 : override for lnx_rstn [3:2] : override for lnx_rate [5:4] : override for lnX_pd [48:6] : override for lnx_ctrl For SAPIS Mode : 0 : override enable 1 : override for lnx_rstn { [17:15], [3:2]} : override for lnx_rate [5:4] : override for lnX_pd [14:6] : override for lnx_ctrl [48:15] : not used [48:15] : not used
  [15:8] LN_IN_OVR_O_47_40 — Override for primary lane inputs For PCIE3 mode : 0 : override enable 1 : override for lnx_rstn [3:2] : override for lnx_rate [5:4] : override for lnX_pd [48:6] : override for lnx_ctrl For SAPIS Mode : 0 : override enable 1 : override for lnx_rstn { [17:15], [3:2]} : override for lnx_rate [5:4] : override for lnX_pd [14:6] : override for lnx_ctrl [48:15] : not used [48:15] : not used
  [7:0] LN_IN_OVR_O_39_32 — Override for primary lane inputs For PCIE3 mode : 0 : override enable 1 : override for lnx_rstn [3:2] : override for lnx_rate [5:4] : override for lnX_pd [48:6] : override for lnx_ctrl For SAPIS Mode : 0 : override enable 1 : override for lnx_rstn { [17:15], [3:2]} : override for lnx_rate [5:4] : override for lnX_pd [14:6] : override for lnx_ctrl [48:15] : not used [48:15] : not used
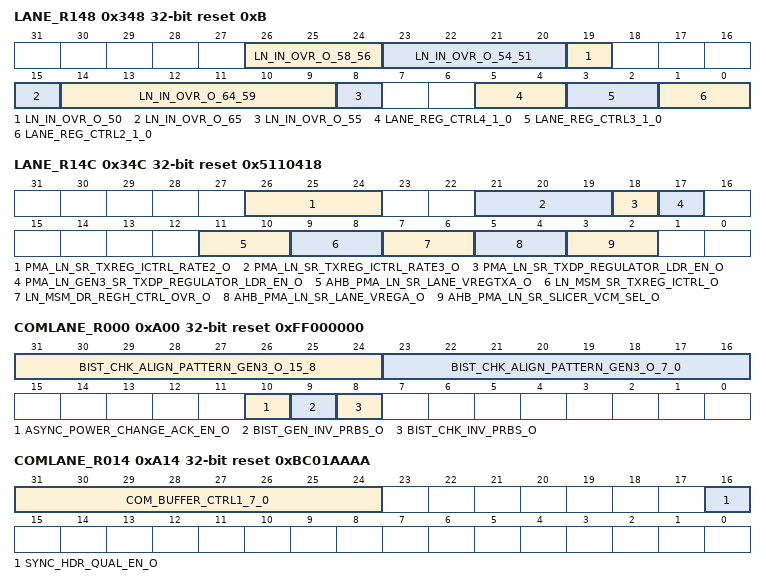
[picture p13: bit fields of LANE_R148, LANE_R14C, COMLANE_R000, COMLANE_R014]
0x348 LANE_R148 reset 0xB — The lane_148 register
  [26:24] LN_IN_OVR_O_58_56 — Override signals for lane: main interface control [57:55]
  [23:20] LN_IN_OVR_O_54_51 — Override signals for lane: main interface control [46:43]
  [19] LN_IN_OVR_O_50 — Override signals for lane: msm_ln_rate_ow [4:2]
  [15] LN_IN_OVR_O_65 — Lane Reset
  [14:9] LN_IN_OVR_O_64_59 — Override signals for lane: main interface control [53:48]
  [8] LN_IN_OVR_O_55 — Override signals for lane: main interface control[47]
  [5:4] LANE_REG_CTRL4_1_0 — LANE regulator control 4 register [1:0]
  [3:2] LANE_REG_CTRL3_1_0 — LANE regulator control 3 register [1:0]
  [1:0] LANE_REG_CTRL2_1_0 — LANE regulator control 2 register [1:0]
0x34C LANE_R14C reset 0x5110418 — The lane_14c register
  [26:24] PMA_LN_SR_TXREG_ICTRL_RATE2_O — Tx regulator integral path control setting for PCIe3 Gen3 rate
  [21:19] PMA_LN_SR_TXREG_ICTRL_RATE3_O — Tx regulator integral path control setting for PCIe3 Gen3 rate
  [18] PMA_LN_SR_TXDP_REGULATOR_LDR_EN_O — Txdp regulator enable for PCIe Gen1/2 rate
  [17] PMA_LN_GEN3_SR_TXDP_REGULATOR_LDR_EN_O — Txdp regulator enable for PCIe Gen3 rate
  [11:10] AHB_PMA_LN_SR_LANE_VREGTXA_O — Lane VREGTXA setting
  [9:8] LN_MSM_SR_TXREG_ICTRL_O — vco regulator override
  [7:6] LN_MSM_DR_REGH_CTRL_OVR_O — vco regulator override
  [5:4] AHB_PMA_LN_SR_LANE_VREGA_O — Lane VREGA setting
  [3:2] AHB_PMA_LN_SR_SLICER_VCM_SEL_O — Slicer common mode select
0xA00 COMLANE_R000 reset 0xFF000000 — The comlane_000 register
  [31:24] BIST_CHK_ALIGN_PATTERN_GEN3_O_15_8 — BIST alignment pattern for Gen3
  [23:16] BIST_CHK_ALIGN_PATTERN_GEN3_O_7_0 — BIST alignment pattern for Gen3
  [10] ASYNC_POWER_CHANGE_ACK_EN_O — When asserted supports PIPE 4-3 spec
  [9] BIST_GEN_INV_PRBS_O — Enable/Disable the internal PRBS data pattern inverter. 0x0 Invert the PRBS data pattern for PRBS-31 and not invert the PRBS data pattern for the other PRBS types. 0x1 Not invert the PRBS data pattern for PRBS-31 and invert the PRBS data pattern for the other PRBS types.
  [8] BIST_CHK_INV_PRBS_O — Enable/Disable the internal PRBS data pattern inverter. 0x0 Invert the PRBS data pattern for PRBS-31 and not invert the PRBS data pattern for the other PRBS types. 0x1 Not invert the PRBS data pattern for PRBS-31 and invert the PRBS data pattern for the other PRBS types.
0xA14 COMLANE_R014 reset 0xBC01AAAA — The comlane_014 register
  [31:24] COM_BUFFER_CTRL1_7_0 — COMLANE buffer control 1 register [7:0]
  [16] SYNC_HDR_QUAL_EN_O — Enables block_aligner skpos_hdr_det qualification
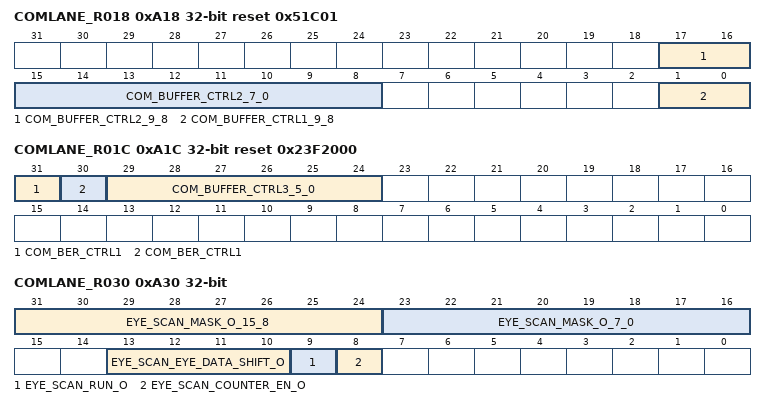
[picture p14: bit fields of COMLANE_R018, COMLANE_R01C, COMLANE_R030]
0xA18 COMLANE_R018 reset 0x51C01 — The comlane_018 register
  [17:16] COM_BUFFER_CTRL2_9_8 — COMLANE buffer control 2 register [9:8]
  [15:8] COM_BUFFER_CTRL2_7_0 — COMLANE buffer control 2 register [7:0]
  [1:0] COM_BUFFER_CTRL1_9_8 — COMLANE buffer control 1 register [9:8]
0xA1C COMLANE_R01C reset 0x23F2000 — The comlane_01c register
  [31] COM_BER_CTRL1 — COMLANE ber control 1 register
  [30] COM_BER_CTRL1 — COMLANE beacon control 1 register
  [29:24] COM_BUFFER_CTRL3_5_0 — COMLANE buffer control 3 register [5:0]
0xA30 COMLANE_R030 — The comlane_030 register
  [31:24] EYE_SCAN_MASK_O_15_8 — Mask eye scan results
  [23:16] EYE_SCAN_MASK_O_7_0 — Mask eye scan results
  [13:10] EYE_SCAN_EYE_DATA_SHIFT_O — Shift edge samples
  [9] EYE_SCAN_RUN_O — Run eye scan counter
  [8] EYE_SCAN_COUNTER_EN_O — Enable eye scan counter
